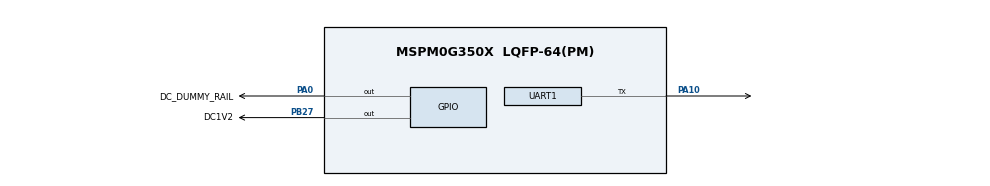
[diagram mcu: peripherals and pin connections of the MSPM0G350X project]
/**
 * @cliArgs --device "MSPM0G350X" --package "LQFP-64(PM)" --part "Default" --product "mspm0_sdk@2.00.01.01"
 * @versions {"tool":"1.19.0+3426"}
 */

/**
 * Import the modules used in this configuration.
 */
const ADC12  = scripting.addModule("/ti/driverlib/ADC12", {}, false);
const ADC121 = ADC12.addInstance();
const Board  = scripting.addModule("/ti/driverlib/Board");
const GPIO   = scripting.addModule("/ti/driverlib/GPIO", {}, false);
const GPIO1  = GPIO.addInstance();
const GPIO2  = GPIO.addInstance();
const SYSCTL = scripting.addModule("/ti/driverlib/SYSCTL");
const UART   = scripting.addModule("/ti/driverlib/UART", {}, false);
const UART1  = UART.addInstance();

/**
 * Write custom configuration values to the imported modules.
 */
ADC121.$name                      = "ADC12_0";
ADC121.sampClkSrc                 = "DL_ADC12_CLOCK_ULPCLK";
ADC121.sampClkDiv                 = "DL_ADC12_CLOCK_DIVIDE_8";
ADC121.adcMem0chansel             = "DL_ADC12_INPUT_CHAN_2";
ADC121.sampleTime0                = "125 us";
ADC121.enabledInterrupts          = ["DL_ADC12_INTERRUPT_MEM0_RESULT_LOADED"];
ADC121.powerDownMode              = "DL_ADC12_POWER_DOWN_MODE_MANUAL";
ADC121.peripheral.$assign         = "ADC0";
ADC121.peripheral.adcPin2.$assign = "PA25";
ADC121.adcPin2Config.$name        = "ti_driverlib_gpio_GPIOPinGeneric0";


GPIO1.port                          = "PORTB";
GPIO1.$name                         = "GPIOB_ENABLE";
GPIO1.associatedPins[0].$name       = "DC1V2";
GPIO1.associatedPins[0].pin.$assign = "PB27";

GPIO2.$name                          = "GPIOA_ENABLE";
GPIO2.port                           = "PORTA";
GPIO2.associatedPins[0].$name        = "DC_DUMMY_RAIL";
GPIO2.associatedPins[0].initialValue = "SET";
GPIO2.associatedPins[0].pin.$assign  = "PA0";

SYSCTL.forceDefaultClkConfig = true;

UART1.$name                    = "UART_0";
UART1.rxFifoThreshold          = "DL_UART_RX_FIFO_LEVEL_ONE_ENTRY";
UART1.direction                = "TX";
UART1.txFifoThreshold          = "DL_UART_TX_FIFO_LEVEL_EMPTY";
UART1.enabledInterrupts        = ["TX"];
UART1.peripheral.$assign       = "UART0";
UART1.peripheral.txPin.$assign = "PA10";
UART1.txPinConfig.$name        = "ti_driverlib_gpio_GPIOPinGeneric1";

/**
 * Pinmux solution for unlocked pins/peripherals. This ensures that minor changes to the automatic solver in a future
 * version of the tool will not impact the pinmux you originally saw.  These lines can be completely deleted in order to
 * re-solve from scratch.
 */
Board.peripheral.$suggestSolution          = "DEBUGSS";
Board.peripheral.swclkPin.$suggestSolution = "PA20";
Board.peripheral.swdioPin.$suggestSolution = "PA19";
SYSCTL.peripheral.$suggestSolution         = "SYSCTL";
